# AM13E230x register map
Vendor: Texas Instruments; File version: Revised: 2025-12-26 17:30:06
CPU: CM33 r0p0, little endian, MPU, FPU, 4 interrupt priority bits
Registers are 32-bit, read-write, reset 0x0 unless marked. A register's access mark holds for its fields unless they carry their own. Offsets are from the block's base; [hi:lo] are bit positions; {n}, {i} and the like mark numbered series; 'fields as' and 'values as' point back to an identical list.

## EQEP0 — EQEP_REGS
Base 0x40448000
Same registers: EQEP1 0x40449000, EQEP2 0x4044A000
0x00 QPOSCNT — Position Counter
0x04 QPOSINIT — Position Counter Init
0x08 QPOSMAX — Maximum Position Count
0x0C QPOSCMP — Position Compare
0x10 QPOSILAT — Index Position Latch
0x14 QPOSSLAT — Strobe Position Latch
0x18 QPOSLAT — Position Latch
0x1C QUTMR — QEP Unit Timer
0x20 QUPRD — QEP Unit Period
0x24 QWDTMR 16-bit — QEP Watchdog Timer
0x26 QWDPRD 16-bit — QEP Watchdog Period
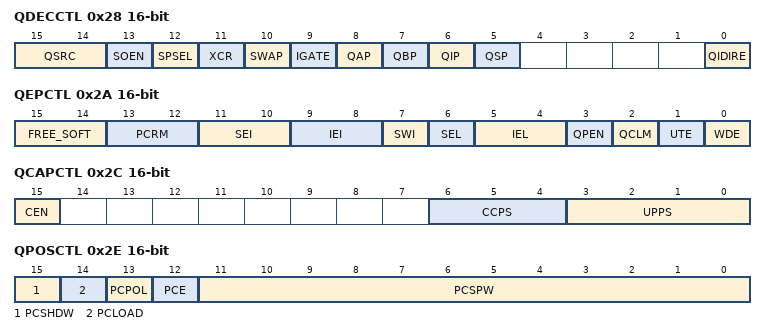
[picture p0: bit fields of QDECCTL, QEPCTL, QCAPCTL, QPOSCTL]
0x28 QDECCTL 16-bit — Quadrature Decoder Control
  [15:14] QSRC — Position-counter source selection
    0=QUAD (Quadrature count mode (QCLK = iCLK, QDIR = iDIR)); 1=DIRECT (Direction-count mode (QCLK = xCLK, QDIR = xDIR)); 2=UP (UP count mode for frequency measurement (QCLK = xCLK, QDIR = 1)); 3=DOWN (DOWN count mode for frequency measurement (QCLK = xCLK, QDIR = 0))
  [13] SOEN — Sync output-enable
    0=DISABLE (Disable position-compare sync output); 1=ENABLE (Enable position-compare sync output)
  [12] SPSEL — Sync output pin selection
    0=INDEX (Index pin is used for sync output); 1=STROBE (Strobe pin is used for sync output)
  [11] XCR — External Clock Rate
    0=XCR_2XRESOL (2x resolution: Count the rising/falling edge); 1=XCR_1XRESOL (1x resolution: Count the rising edge only)
  [10] SWAP — CLK/DIR Signal Source for Position Counter
    0=DISABLE (Quadrature-clock inputs are not swapped); 1=ENABLE (Quadrature-clock inputs are swapped)
  [9] IGATE — Index pulse gating option
    0=DISABLE (Disable gating of Index pulse); 1=ENABLE (Gate the index pin with strobe)
  [8] QAP — QEPA input polarity
    0=NOPOLAR (No effect); 1=POLAR (Negates QEPA input)
  [7] QBP — QEPB input polarity
    0=NOPOLAR (No effect); 1=POLAR (Negates QEPB input)
  [6] QIP — QEPI input polarity
    0=NOPOLAR (No effect); 1=POLAR (Negates QEPI input)
  [5] QSP — QEPS input polarity
    0=NOPOLAR (No effect); 1=POLAR (Negates QEPS input)
  [0] QIDIRE — Qep Index Direction Enhancement enable
0x2A QEPCTL 16-bit — QEP Control
  [15:14] FREE_SOFT — Emulation mode
    0=QPOSCNT behavior #br#Position counter stops immediately on emulation suspend #br#0h (R/W) = QWDTMR behavior #br#Watchdog counter stops immediately #br#0h (R/W) = QUTMR behavior #br#Unit timer stops immediately #br#0h (R/W) = QCTMR behavior #br#Capture Timer stops immediately; 1=QPOSCNT behavior #br#Position counter continues to count until the rollover #br#1h (R/W) = QWDTMR behavior #br#Watchdog counter counts until WD period match roll over #br#1h (R/W) = QUTMR behavior #br#Unit timer counts until period rollover #br#1h (R/W) = QCTMR behavior #br#Capture Timer counts until next unit period event; 2=QPOSCNT behavior #br#Position counter is unaffected by emulation suspend #br#2h (R/W) = QWDTMR behavior #br#Watchdog counter is unaffected by emulation suspend #br#2h (R/W) = QUTMR behavior #br#Unit timer is unaffected by emulation suspend #br#2h (R/W) = QCTMR behavior #br#Capture Timer is unaffected by emulation suspend; 3=Same as FREE_SOFT_2
  [13:12] PCRM — Postion counter reset
    0=INDEX (Position counter reset on an index event); 1=MAXPOS (Position counter reset on the maximum position); 2=FIRSTINDEX (Position counter reset on the first index event); 3=TIMEEVENT (Position counter reset on a unit time event)
  [11:10] SEI — Strobe event init
    0=NOTHING0 (Does nothing (action disabled)); 1=NOTHING1 (Does nothing (action disabled)); 2=INITQEPSRISING (Initializes the position counter on rising edge of the QEPS signal); 3=INITQEPSCLOCK (Clockwise Direction: #br#Initializes the position counter on the rising edge of QEPS strobe #br#Counter Clockwise Direction: #br#Initializes the position counter on the falling edge of QEPS strobe)
  [9:8] IEI — Index event init of position count
    0=NOTHING0 (Do nothing (action disabled)); 1=NOTHING1 (Do nothing (action disabled)); 2=INITRISING (Initializes the position counter on the rising edge of the QEPI signal (QPOSCNT = QPOSINIT)); 3=INITFALLING (Initializes the position counter on the falling edge of QEPI signal (QPOSCNT = QPOSINIT))
  [7] SWI — Software init position counter
    0=NOTHING (Do nothing (action disabled)); 1=INITPOS (Initialize position counter (QPOSCNT=QPOSINIT). This bit is not cleared automatically)
  [6] SEL — Strobe event latch
    0=QEPSRISING (The position counter is latched on the rising edge of QEPS strobe (QPOSSLAT = POSCCNT). Latching on the falling edge can be done by inverting the strobe input using the QSP bit in the QDECCTL register); 1=QEPSCLOCK (Clockwise Direction: #br#Position counter is latched on rising edge of QEPS strobe #br#Counter Clockwise Direction: #br#Position counter is latched on falling edge of QEPS strobe)
  [5:4] IEL — Index event latch
    1=POSRISING (Latches position counter on rising edge of the index signal); 2=POSFALLING (Latches position counter on falling edge of the index signal); 3=SIM (Software index marker. Latches the position counter and quadrature direction flag on index event marker. The position counter is latched to the QPOSILAT register and the direction flag is latched in the QEPSTS[QDLF] bit. This mode is useful for software index marking.)
  [3] QPEN — Quadrature postotion counter enable
    0=RESET (Reset the eQEP peripheral internal operating flags/read-only registers. Control/configuration registers are not disturbed by a software reset. #br#When QPEN is disabled, some flags in the QFLG register do not get reset or cleared and show the actual state of that flag.); 1=ENABLE (eQEP position counter is enabled)
  [2] QCLM — QEP capture latch mode
    0=CPU (Latch on position counter read by CPU. Capture timer and capture period values are latched into QCTMRLAT and QCPRDLAT registers when CPU reads the QPOSCNT register.); 1=TIMEOUT (Latch on unit time out. Position counter, capture timer and capture period values are latched into QPOSLAT, QCTMRLAT and QCPRDLAT registers on unit time out.)
  [1] UTE — QEP unit timer enable
    0=DISABLE (Disable eQEP unit timer); 1=ENABLE (Enable unit timer)
  [0] WDE — QEP watchdog enable
    0=DISABLE (Disable the eQEP watchdog timer); 1=ENABLE (Enable the eQEP watchdog timer)
0x2C QCAPCTL 16-bit — Qaudrature Capture Control
  [15] CEN — Enable eQEP capture
    0=DISABLE (eQEP capture unit is disabled); 1=ENABLE (eQEP capture unit is enabled)
  [6:4] CCPS — eQEP capture timer clock prescaler
    0=SYSCLKOUT1 (CAPCLK = SYSCLKOUT/1); 1=SYSCLKOUT2 (CAPCLK = SYSCLKOUT/2); 2=SYSCLKOUT4 (CAPCLK = SYSCLKOUT/4); 3=SYSCLKOUT8 (CAPCLK = SYSCLKOUT/8); 4=SYSCLKOUT16 (CAPCLK = SYSCLKOUT/16); 5=SYSCLKOUT32 (CAPCLK = SYSCLKOUT/32); 6=SYSCLKOUT64 (CAPCLK = SYSCLKOUT/64); 7=SYSCLKOUT128 (CAPCLK = SYSCLKOUT/128)
  [3:0] UPPS — Unit position event prescaler
    0=QCLK1 (UPEVNT = QCLK/1); 1=QCLK2 (UPEVNT = QCLK/2); 2=QCLK4 (UPEVNT = QCLK/4); 3=QCLK8 (UPEVNT = QCLK/8); 4=QCLK16 (UPEVNT = QCLK/16); 5=QCLK32 (UPEVNT = QCLK/32); 6=QCLK64 (UPEVNT = QCLK/64); 7=QCLK128 (UPEVNT = QCLK/128); 8=QCLK256 (UPEVNT = QCLK/256); 9=QCLK512 (UPEVNT = QCLK/512); 10=QCLK1024 (UPEVNT = QCLK/1024); 11=QCLK2048 (UPEVNT = QCLK/2048); {v}=QCLK_RSVD{v-12} (Reserved) (v=12..15)
0x2E QPOSCTL 16-bit — Position Compare Control
  [15] PCSHDW — Position compare of shadow enable
    0=DISABLE (Shadow disabled, load Immediate); 1=ENABLE (Shadow enabled)
  [14] PCLOAD — Position compare of shadow load
    0=Load on QPOSCNT = 0; 1=PCLOAD_QPOSCMP (Load when QPOSCNT = QPOSCMP)
  [13] PCPOL — Polarity of sync output
    0=HIGH (Active HIGH pulse output); 1=LOW (Active LOW pulse output)
  [12] PCE — Position compare enable/disable
    0=DISABLE (Disable position compare unit); 1=ENABLE (Enable position compare unit)
  [11:0] PCSPW — Position compare sync pulse width
    0=SYSCLKOUT4 (1 * 4 * SYSCLKOUT cycles); 1=SYSCLKOUT8 (2 * 4 * SYSCLKOUT cycles); 0xFFF=SYSCLKOUT16384 (4096 * 4 * SYSCLKOUT cycles)
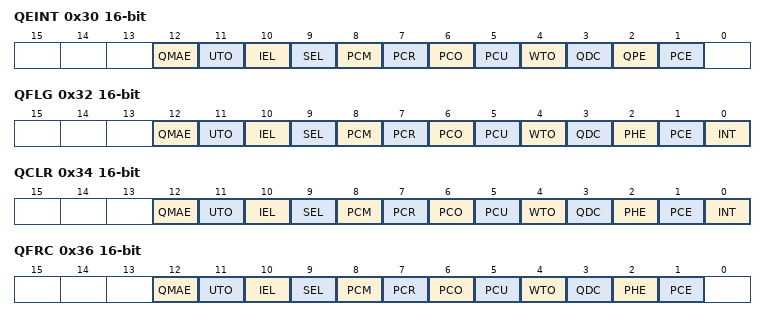
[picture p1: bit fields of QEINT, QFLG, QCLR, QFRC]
0x30 QEINT 16-bit — QEP Interrupt Control
  [all] fields
    0=DISABLE (Interrupt is disabled); 1=ENABLE (Interrupt is enabled)
  [12] QMAE — QMA error interrupt enable
  [11] UTO — Unit time out interrupt enable
  [10] IEL — Index event latch interrupt enable
  [9] SEL — Strobe event latch interrupt enable
  [8] PCM — Position-compare match interrupt enable
  [7] PCR — Position-compare ready interrupt enable
  [6] PCO — Position counter overflow interrupt enable
  [5] PCU — Position counter underflow interrupt enable
  [4] WTO — Watchdog time out interrupt enable
  [3] QDC — Quadrature direction change interrupt enable
  [2] QPE — Quadrature phase error interrupt enable
  [1] PCE — Position counter error interrupt enable
0x32 QFLG 16-bit — QEP Interrupt Flag
  [12] QMAE ro — QMA error interrupt flag
    0=NOFLAG (No interrupt generated); 1=FLAG (Interrupt was generated)
  [11] UTO ro — Unit time out interrupt flag
    0=NOFLAG (No interrupt generated); 1=FLAG (Set by eQEP unit timer period match)
  [10] IEL ro — Index event latch interrupt flag
    0=NOFLAG (No interrupt generated); 1=FLAG (This bit is set after latching the QPOSCNT to QPOSILAT)
  [9] SEL ro — Strobe event latch interrupt flag
    0=NOFLAG (No interrupt generated); 1=FLAG (This bit is set after latching the QPOSCNT to QPOSSLAT)
  [8] PCM ro — eQEP compare match event interrupt flag
    0=NOFLAG (No interrupt generated); 1=FLAG (This bit is set on position-compare match)
  [7] PCR ro — Position-compare ready interrupt flag
    0=NOFLAG (No interrupt generated); 1=FLAG (This bit is set after transferring the shadow register value to the active position compare register)
  [6] PCO ro — Position counter overflow interrupt flag
    0=NOFLAG (No interrupt generated); 1=FLAG (This bit is set on position counter overflow.)
  [5] PCU ro — Position counter underflow interrupt flag
    0=NOFLAG (No interrupt generated); 1=FLAG (This bit is set on position counter underflow.)
  [4] WTO ro — Watchdog timeout interrupt flag
    0=NOFLAG (No interrupt generated); 1=FLAG (Set by watchdog timeout)
  [3] QDC ro — Quadrature direction change interrupt flag
    values as QMAE
  [2] PHE ro — Quadrature phase error interrupt flag
    0=NOFLAG (No interrupt generated); 1=FLAG (Set on simultaneous transition of QEPA and QEPB)
  [1] PCE ro — Position counter error interrupt flag
    0=NOFLAG (No interrupt generated); 1=FLAG (Position counter error)
  [0] INT ro — Global interrupt status flag
    values as QMAE
0x34 QCLR 16-bit — QEP Interrupt Clear
  [12] QMAE — Clear QMA error interrupt flag
  [11] UTO — Clear unit time out interrupt flag
  [10] IEL — Clear index event latch interrupt flag
  [9] SEL — Clear strobe event latch interrupt flag
  [8] PCM — Clear eQEP compare match event interrupt flag
  [7] PCR — Clear position-compare ready interrupt flag
  [6] PCO — Clear position counter overflow interrupt flag
  [5] PCU — Clear position counter underflow interrupt flag
  [4] WTO — Clear watchdog timeout interrupt flag
  [3] QDC — Clear quadrature direction change interrupt flag
  [2] PHE — Clear quadrature phase error interrupt flag
  [1] PCE — Clear position counter error interrupt flag
  [0] INT — Global interrupt clear flag
0x36 QFRC 16-bit — QEP Interrupt Force
  [12] QMAE — Force QMA error interrupt
  [11] UTO — Force unit time out interrupt
  [10] IEL — Force index event latch interrupt
  [9] SEL — Force strobe event latch interrupt
  [8] PCM — Force position-compare match interrupt
  [7] PCR — Force position-compare ready interrupt
  [6] PCO — Force position counter overflow interrupt
  [5] PCU — Force position counter underflow interrupt
  [4] WTO — Force watchdog time out interrupt
  [3] QDC — Force quadrature direction change interrupt
  [2] PHE — Force quadrature phase error interrupt
  [1] PCE — Force position counter error interrupt
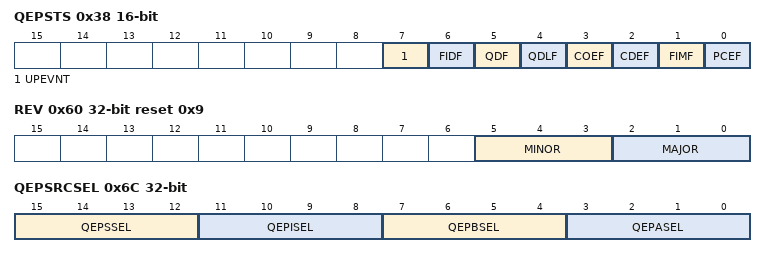
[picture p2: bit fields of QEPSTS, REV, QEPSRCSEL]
0x38 QEPSTS 16-bit — QEP Status
  [7] UPEVNT — Unit position event flag
    0=NODETCT (No unit position event detected); 1=DETCT (Unit position event detected. Write 1 to clear)
  [6] FIDF ro — The first index marker
    0=COUNTERCLK (Counter-clockwise rotation (or reverse movement) on the first index event); 1=CLK (Clockwise rotation (or forward movement) on the first index event)
  [5] QDF ro — Quadrature direction flag
    0=COUNTERCLK (Counter-clockwise rotation (or reverse movement)); 1=CLK (Clockwise rotation (or forward movement))
  [4] QDLF ro — eQEP direction latch flag
    0=COUNTERCLK (Counter-clockwise rotation (or reverse movement) on index event marker); 1=CLK (Clockwise rotation (or forward movement) on index event marker)
  [3] COEF — Capture overflow error flag
    0=WRT1 (Overflow has not occurred.); 1=OVF (Overflow occurred in eQEP Capture timer (QEPCTMR). This bit is cleared by writing a '1'.)
  [2] CDEF — Capture direction error flag
    0=WRT1 (Capture direction error has not occurred.); 1=DIRECT (Direction change occurred between the capture position event. This bit is cleared by writing a '1'.)
  [1] FIMF — First index marker flag
    0=WRT1 (First index pulse has not occurred.); 1=SETINDEX (Set by first occurrence of index pulse. This bit is cleared by writing a '1'.)
  [0] PCEF ro — Position counter error flag.
    0=NOERROR (No error occurred during the last index transition); 1=ERROR (Position counter error)
0x3A QCTMR 16-bit — QEP Capture Timer
0x3C QCPRD 16-bit — QEP Capture Period
0x3E QCTMRLAT 16-bit — QEP Capture Latch
0x40 QCPRDLAT 16-bit — QEP Capture Period Latch
0x60 REV reset 0x9 — QEP Revision Number
  [5:3] MINOR ro — Minor Revision Number
  [2:0] MAJOR ro — Major Revision Number
0x64 QEPSTROBESEL — QEP Strobe select register
  [1:0] STROBESEL — QMA Mode Select
    0=QS_AFTER_POL_MUX (QEP Strobe after polarity mux); 2=ADCSOCA_AS_QS (QEP Strobe after polarity mux ORed with ADCSOCA); 3=ADCSOCB_AS_QS (QEP Strobe after polarity mux ORed with ADCSOCB)
0x68 QMACTRL — QMA Control register
  [2:0] MODE — QMA Mode Select
0x6C QEPSRCSEL — QEP Source Select Register
  [15:12] QEPSSEL — QEPS Source select
  [11:8] QEPISEL — QEPI Source select
  [7:4] QEPBSEL — QEPB Source select
  [3:0] QEPASEL — QEPA Source select
